# PIC16LF1708 register map
Vendor: Microchip
Architecture 16Exxx. Special function registers and configuration words.
Registers are 8-bit, read-write, reset 0x0 unless marked. A register's access mark holds for its fields unless they carry their own. Addresses are absolute, and some are shared; only a register's first bit layout is shown; lines under a group give offsets from that group; [hi:lo] are bit positions; {n}, {i} and the like mark numbered series; 'fields as' and 'values as' point back to an identical list; <NAME> marks a mode.

## Further device data
pins=1: VDD; 2: RA5/T1CKI/SOSCI/CLKIN/OSC1; 3: RA4/AN3/SOSCO/CLKOUT/OSC2; 4: RA3/MCLR/VPP; 5: RC5; 6: RC4; 7: RC3/AN7/C1IN3-/C2IN3-/OPA2OUT; 8: RC6/AN8/OPA2IN-; 9: RC7/AN9/OPA2IN+; 10: RB7; 11: RB6; 12: RB5/AN11/OPA1IN+; 13: RB4/AN10/OPA1IN-; 14: RC2/AN6/C1IN2-/C2IN2-/OPA1OUT; 15: RC1/AN5/C1IN1-/C2IN1-; 16: RC0/AN4/C2IN+; 17: RA2/AN2/DAC1OUT2/ZCD; 18: RA1/AN1/VREF+/C1IN0-/C2IN0-/ICSPCLK/ICDCLK; 19: RA0/AN0/VREF-/C1IN+/DAC1OUT1/ICSPDAT/ICDDAT; 20: VSS

## tmr
0x1A TMR2 — 8-bit period timer
0x1B PR2 reset 0xFF
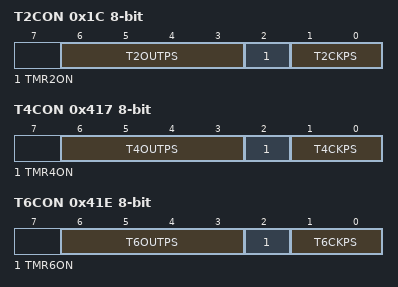
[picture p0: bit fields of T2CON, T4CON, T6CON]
0x1C T2CON
  [6:3] T2OUTPS, [2] TMR2ON, [1:0] T2CKPS
0x415 TMR4 — 8-bit period timer
0x416 PR4 reset 0xFF
0x417 T4CON
  [6:3] T4OUTPS, [2] TMR4ON, [1:0] T4CKPS
0x41C TMR6 — 8-bit period timer
0x41D PR6 reset 0xFF
0x41E T6CON
  [6:3] T6OUTPS, [2] TMR6ON, [1:0] T6CKPS

## cmp_rr
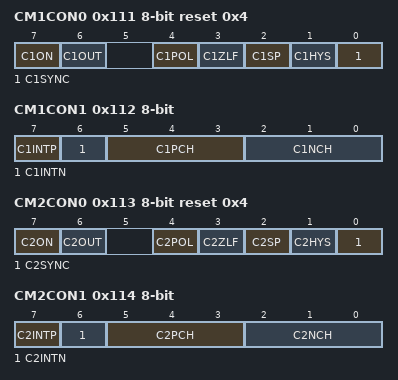
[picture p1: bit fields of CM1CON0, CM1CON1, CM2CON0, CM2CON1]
0x111 CM1CON0 reset 0x4
  [7] C1ON, [6] C1OUT ro, [4] C1POL, [3] C1ZLF, [2] C1SP, [1] C1HYS, [0] C1SYNC
0x112 CM1CON1
  [7] C1INTP, [6] C1INTN, [5:3] C1PCH, [2:0] C1NCH
0x113 CM2CON0 reset 0x4
  [7] C2ON, [6] C2OUT ro, [4] C2POL, [3] C2ZLF, [2] C2SP, [1] C2HYS, [0] C2SYNC
0x114 CM2CON1
  [7] C2INTP, [6] C2INTN, [5:3] C2PCH, [2:0] C2NCH

## 8bit_DAC
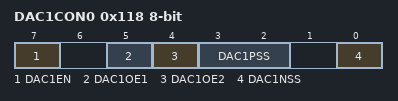
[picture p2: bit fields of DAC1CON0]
0x118 DAC1CON0
  [7] DAC1EN, [5] DAC1OE1, [4] DAC1OE2, [3:2] DAC1PSS, [0] DAC1NSS
0x119 DAC1CON1
  [7:0] DAC1R

## cmp_zxover_ctrl
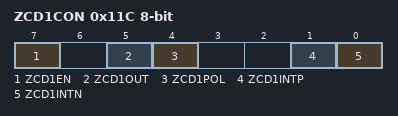
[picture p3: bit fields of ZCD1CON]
0x11C ZCD1CON reset not defined — (power-on value 0-x0--00)
  [7] ZCD1EN, [5] ZCD1OUT ro, [4] ZCD1POL, [1] ZCD1INTP, [0] ZCD1INTN

## mssp
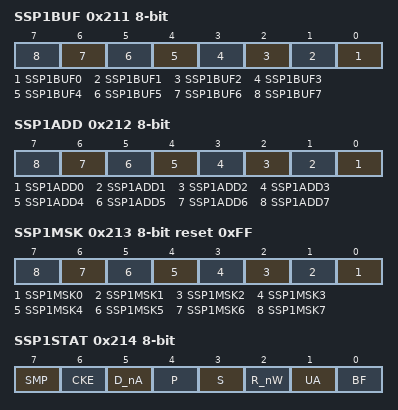
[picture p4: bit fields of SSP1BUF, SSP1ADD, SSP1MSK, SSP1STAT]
0x211 SSP1BUF reset not defined — (power-on value xxxxxxxx)
  [n] SSP1BUF{n} (n=0..7)
0x212 SSP1ADD
  [n] SSP1ADD{n} (n=0..7)
0x213 SSP1MSK reset 0xFF
  [n] SSP1MSK{n} (n=0..7)
0x214 SSP1STAT
  [7] SMP, [6] CKE, [5] D_nA ro, [4] P ro, [3] S ro, [2] R_nW ro, [1] UA ro, [0] BF ro
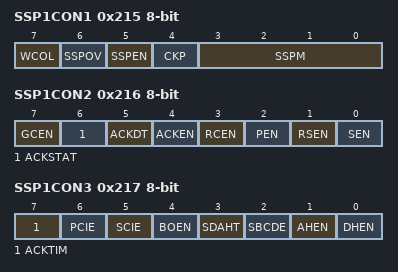
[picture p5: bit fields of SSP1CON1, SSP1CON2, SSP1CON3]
0x215 SSP1CON1
  [7] WCOL ro, [6] SSPOV ro, [5] SSPEN, [4] CKP, [3:0] SSPM
0x216 SSP1CON2
  [7] GCEN, [6] ACKSTAT ro, [5] ACKDT, [4] ACKEN, [3] RCEN, [2] PEN, [1] RSEN, [0] SEN
0x217 SSP1CON3
  [7] ACKTIM ro, [6] PCIE, [5] SCIE, [4] BOEN, [3] SDAHT, [2] SBCDE, [1] AHEN, [0] DHEN

## ccp
0x291 CCPR1L reset not defined — (power-on value xxxxxxxx)
0x292 CCPR1H reset not defined — (power-on value xxxxxxxx)
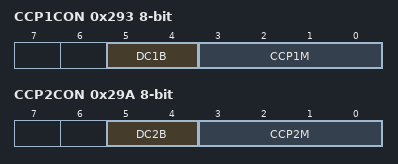
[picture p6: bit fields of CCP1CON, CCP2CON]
0x293 CCP1CON
  [5:4] DC1B, [3:0] CCP1M
0x298 CCPR2L reset not defined — (power-on value xxxxxxxx)
0x299 CCPR2H reset not defined — (power-on value xxxxxxxx)
0x29A CCP2CON
  [5:4] DC2B, [3:0] CCP2M

## amp_opamp_hvpump
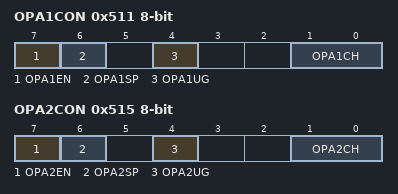
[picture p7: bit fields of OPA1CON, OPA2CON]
0x511 OPA1CON
  [7] OPA1EN, [6] OPA1SP, [4] OPA1UG, [1:0] OPA1CH
0x515 OPA2CON
  [7] OPA2EN, [6] OPA2SP, [4] OPA2UG, [1:0] OPA2CH

## cog
0x691 COG1PHR reset not defined — (power-on value --xxxxxx)
  [5:0] G1PHR
0x692 COG1PHF reset not defined — (power-on value --xxxxxx)
  [5:0] G1PHF
0x693 COG1BLKR reset not defined — (power-on value --xxxxxx)
  [5:0] G1BLKR
0x694 COG1BLKF reset not defined — (power-on value --xxxxxx)
  [5:0] G1BLKF
0x695 COG1DBR reset not defined — (power-on value --xxxxxx)
  [5:0] G1DBR
0x696 COG1DBF reset not defined — (power-on value --xxxxxx)
  [5:0] G1DBF
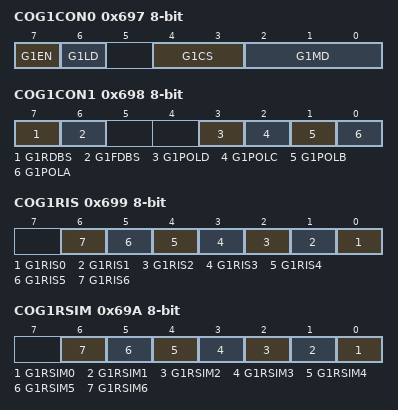
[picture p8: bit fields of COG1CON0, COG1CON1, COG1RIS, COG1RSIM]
0x697 COG1CON0
  [7] G1EN, [6] G1LD, [4:3] G1CS, [2:0] G1MD
0x698 COG1CON1
  [7] G1RDBS, [6] G1FDBS, [3] G1POLD, [2] G1POLC, [1] G1POLB, [0] G1POLA
0x699 COG1RIS
  [n] G1RIS{n} (n=0..6)
0x69A COG1RSIM
  [n] G1RSIM{n} (n=0..6)
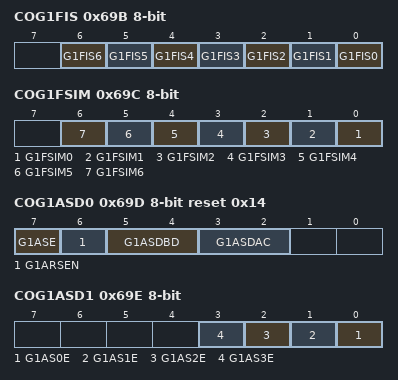
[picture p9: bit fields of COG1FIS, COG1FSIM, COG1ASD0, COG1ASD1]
0x69B COG1FIS
  [n] G1FIS{n} (n=0..6)
0x69C COG1FSIM
  [n] G1FSIM{n} (n=0..6)
0x69D COG1ASD0 reset 0x14
  [7] G1ASE, [6] G1ARSEN, [5:4] G1ASDBD, [3:2] G1ASDAC
0x69E COG1ASD1
  [n] G1AS{n}E (n=0..3)
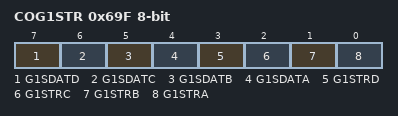
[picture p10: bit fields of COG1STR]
0x69F COG1STR
  [7] G1SDATD, [6] G1SDATC, [5] G1SDATB, [4] G1SDATA, [3] G1STRD, [2] G1STRC, [1] G1STRB, [0] G1STRA
